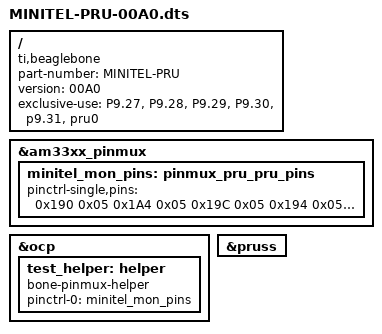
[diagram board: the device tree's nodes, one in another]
 // Compile with:
 // dtc -O dtb -I dts -o /lib/firmware/MINITEL-PRU-00A0.dtbo -b 0 -@ MINITEL-PRU-00A0.dts  
   
 // You'll have to reboot, after which you can do this as root to activate it:  
 // echo PRU-GPIO-EXAMPLE > /sys/devices/bone_capemgr.?/slots  
 
 /dts-v1/;  
 /plugin/;  
 
 / {  
   // This determines which boards can use this DTS overlay  
   compatible = "ti,beaglebone", "ti,beaglebone-green", "ti,beaglebone-black";  
   
   part-number = "MINITEL-PRU";  
   
   // This always seems to be 00A0, and all the .dtbo files in /lib/firmware  
   // seem to be named foo-00A0.dtbo, but then are loaded without that suffix.  So
   // for foo-00A0.dtbo we'd do 'echo foo > /sys/devices/bone_capemgr.?/slots'
   version = "00A0";
   
   exclusive-use =  
	"P9.27", "P9.28", "P9.29", "P9.30", "p9.31",
	"pru0";
   
   fragment@0 {  
    target = <&am33xx_pinmux>;  
    __overlay__ {  
      minitel_mon_pins: pinmux_pru_pru_pins {  
   
       pinctrl-single,pins = <  
	0x190 0x05 // P9 31 (SYNC) r30.0
	0x1A4 0x05 // P9 27 (bit 0) r30.5
	0x19C 0x05 // P9 28 (bit 1) r30.3
	0x194 0x05 // P9 29 (bit 2) r30.1
	0x198 0x05 // P9 30 (bit 3) r30.2
       >;  
      };  
    };  
   };  

  fragment@1 {  
    target = <&ocp>;  
    __overlay__ {  
      test_helper: helper {  
        compatible = "bone-pinmux-helper";  
        pinctrl-names = "default";  
        pinctrl-0 = <&minitel_mon_pins>;  
        status = "okay";  
      };  
    };  
  };  
 
   // This enables the PRU and assigns the GPIO pins to it for use in EGP mode.  
   fragment@2 {  
    target = <&pruss>;  
    __overlay__ {  
      status = "okay";  
    };  
   };  
 };  
  
